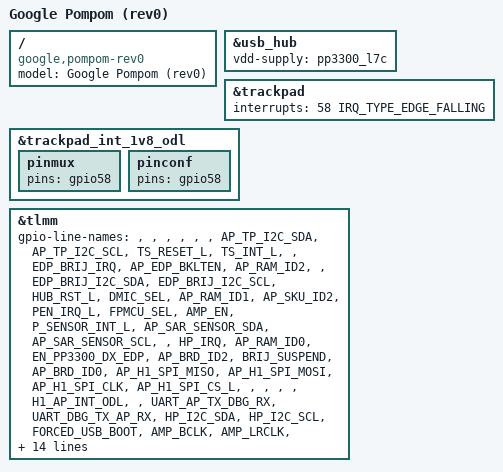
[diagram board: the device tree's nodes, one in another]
// SPDX-License-Identifier: (GPL-2.0+ OR MIT)
/*
 * Google Pompom board device tree source
 *
 * Copyright 2020 Google LLC.
 */

/dts-v1/;

#include "sc7180-trogdor-pompom.dtsi"

/ {
	model = "Google Pompom (rev0)";
	compatible = "google,pompom-rev0", "qcom,sc7180";
};

&usb_hub {
	 vdd-supply = <&pp3300_l7c>;
};

&trackpad {
	interrupts = <58 IRQ_TYPE_EDGE_FALLING>;
};

/* PINCTRL - modifications to sc7180-trogdor.dtsi */

&trackpad_int_1v8_odl {
	pinmux {
		pins = "gpio58";
	};

	pinconf {
		pins = "gpio58";
	};
};

/* PINCTRL - board-specific pinctrl */

&tlmm {
	gpio-line-names = "",
			  "",
			  "",
			  "",
			  "",
			  "",
			  "AP_TP_I2C_SDA",
			  "AP_TP_I2C_SCL",
			  "TS_RESET_L",
			  "TS_INT_L",
			  "",
			  "EDP_BRIJ_IRQ",
			  "AP_EDP_BKLTEN",
			  "AP_RAM_ID2",
			  "",
			  "EDP_BRIJ_I2C_SDA",
			  "EDP_BRIJ_I2C_SCL",
			  "HUB_RST_L",
			  "DMIC_SEL",
			  "AP_RAM_ID1",
			  "AP_SKU_ID2",
			  "PEN_IRQ_L",
			  "FPMCU_SEL",
			  "AMP_EN",
			  "P_SENSOR_INT_L",
			  "AP_SAR_SENSOR_SDA",
			  "AP_SAR_SENSOR_SCL",
			  "",
			  "HP_IRQ",
			  "AP_RAM_ID0",
			  "EN_PP3300_DX_EDP",
			  "AP_BRD_ID2",
			  "BRIJ_SUSPEND",
			  "AP_BRD_ID0",
			  "AP_H1_SPI_MISO",
			  "AP_H1_SPI_MOSI",
			  "AP_H1_SPI_CLK",
			  "AP_H1_SPI_CS_L",
			  "",
			  "",
			  "",
			  "",
			  "H1_AP_INT_ODL",
			  "",
			  "UART_AP_TX_DBG_RX",
			  "UART_DBG_TX_AP_RX",
			  "HP_I2C_SDA",
			  "HP_I2C_SCL",
			  "FORCED_USB_BOOT",
			  "AMP_BCLK",
			  "AMP_LRCLK",
			  "AMP_DIN",
			  "PEN_PDCT_L",
			  "HP_BCLK",
			  "HP_LRCLK",
			  "HP_DOUT",
			  "HP_DIN",
			  "HP_MCLK",
			  "TRACKPAD_INT_1V8_ODL",
			  "AP_EC_SPI_MISO",
			  "AP_EC_SPI_MOSI",
			  "AP_EC_SPI_CLK",
			  "AP_EC_SPI_CS_L",
			  "AP_SPI_CLK",
			  "AP_SPI_MOSI",
			  "AP_SPI_MISO",
			  /*
			   * AP_FLASH_WP_L is crossystem ABI. Schematics
			   * call it BIOS_FLASH_WP_L.
			   */
			  "AP_FLASH_WP_L",
			  "",
			  "AP_SPI_CS0_L",
			  "SD_CD_ODL",
			  "",
			  "",
			  "",
			  "",
			  "",
			  "UIM2_DATA",
			  "UIM2_CLK",
			  "UIM2_RST",
			  "UIM2_PRESENT",
			  "UIM1_DATA",
			  "UIM1_CLK",
			  "UIM1_RST",
			  "",
			  "EN_PP3300_CODEC",
			  "EN_PP3300_HUB",
			  "",
			  "",
			  "",
			  "",
			  "",
			  "AP_SKU_ID1",
			  "AP_RST_REQ",
			  "",
			  "AP_BRD_ID1",
			  "AP_EC_INT_R_L",
			  "",
			  "",
			  "",
			  "",
			  "",
			  "",
			  "",
			  "",
			  "",
			  "EDP_BRIJ_EN",
			  "AP_SKU_ID0",
			  "",
			  "",
			  "",
			  "",
			  "",
			  "",
			  "",
			  "",
			  "",
			  "AP_TS_PEN_I2C_SDA",
			  "AP_TS_PEN_I2C_SCL",
			  "DP_HOT_PLUG_DET",
			  "EC_IN_RW_ODL";
};
